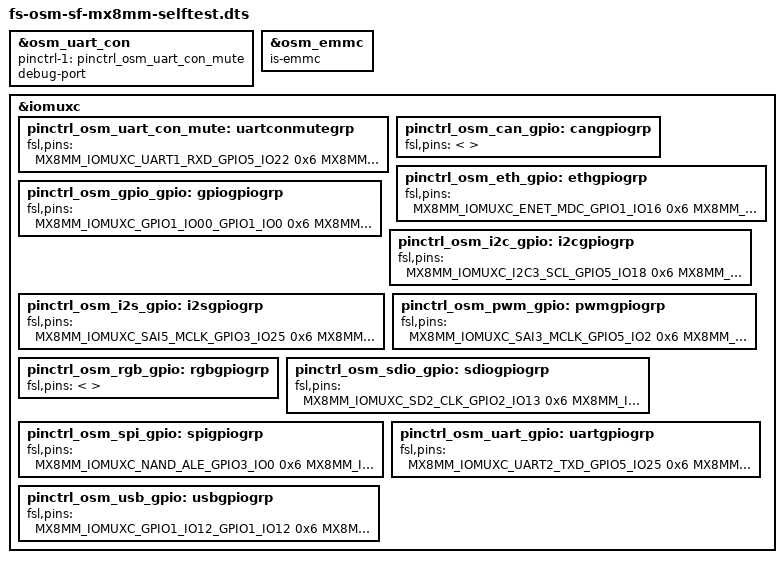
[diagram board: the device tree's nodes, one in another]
// SPDX-License-Identifier: GPL-2.0
/*
* Copyright 2024 F&S Elektronik Systeme GmbH
*
* This program is free software; you can redistribute it and/or modify
* it under the terms of the GNU General Public License version 2 as
* published by the Free Software Foundation.
*
* This program is distributed in the hope that it will be useful,
* but WITHOUT ANY WARRANTY; without even the implied warranty of
* MERCHANTABILITY or FITNESS FOR A PARTICULAR PURPOSE.  See the
* GNU General Public License for more details.
*/

/dts-v1/;
#include "osm8mm.dtsi"

&osm_uart_con { /* console */
	pinctrl-names = "default", "mute";
	pinctrl-1 = <&pinctrl_osm_uart_con_mute>;
	debug-port;
};

&osm_emmc {
	is-emmc;
};

#define gCAN_A_TX			<0>
#define gCAN_A_RX			<0>

#define gCAN_B_TX			<0>
#define gCAN_B_RX			<0>

#define gETH_MDC			<&gpio1 16 0>
#define gETH_MDIO			<&gpio1 17 0>
#define gETH_A_MII_TX_CLK	<&gpio1 23 0>
#define gETH_A_MII_TX_EN	<&gpio1 22 0>
#define gETH_A_MII_TXD0		<&gpio1 21 0>
#define gETH_A_MII_TXD1		<&gpio1 20 0>
#define gETH_A_MII_TXD2		<&gpio1 19 0>
#define gETH_A_MII_TXD3		<&gpio1 18 0>
#define gETH_A_MII_RX_CLK	<&gpio1 25 0>
#define gETH_A_MII_RX_DV	<&gpio1 24 0>
#define gETH_A_MII_RXD0		<&gpio1 26 0>
#define gETH_A_MII_RXD1		<&gpio1 27 0>
#define gETH_A_MII_RXD2		<&gpio1 28 0>
#define gETH_A_MII_RXD3		<&gpio1 29 0>

#define gETH_B_MDC			<0>
#define gETH_B_MDIO			<0>
#define gETH_B_MII_TX_CLK	<0>
#define gETH_B_MII_TX_EN	<0>
#define gETH_B_MII_TXD0		<0>
#define gETH_B_MII_TXD1		<0>
#define gETH_B_MII_TXD2		<0>
#define gETH_B_MII_TXD3		<0>
#define gETH_B_MII_RX_CLK	<0>
#define gETH_B_MII_RX_DV	<0>
#define gETH_B_MII_RXD0		<0>
#define gETH_B_MII_RXD1		<0>
#define gETH_B_MII_RXD2		<0>
#define gETH_B_MII_RXD3		<0>

#define gGPIO_A_0			<&gpio1 0 0>
#define gGPIO_A_1			<&gpio1 1 0>
#define gGPIO_A_2			<&gpio1 4 0>
#define gGPIO_A_3			<&gpio1 5 0>
#define gGPIO_A_4			<&gpio1 6 0>
#define gGPIO_A_5			<&gpio1 7 0>

#define gGPIO_B_0			<&gpio1 8 0>
#define gGPIO_B_1			<&gpio1 9 0>
#define gGPIO_B_2			<&gpio1 10 0>
#define gGPIO_B_3			<&gpio1 11 0>
#define gGPIO_B_4			<&gpio5 7 0>
#define gGPIO_B_5			<&gpio4 9 0>
#define gGPIO_B_6			<&gpio4 8 0>
#define gGPIO_B_7			<&gpio4 7 0>

#define gGPIO_C_0			<&gpio4 6 0>
#define gGPIO_C_1			<&gpio4 5 0>
#define gGPIO_C_2			<&gpio4 4 0>
#define gGPIO_C_3			<&gpio4 3 0>
/* GPIO_C_4 */
#define gDISP_VDD_EN		<&gpio5 1 0>
/* GPIO_C_5 */
#define gDISP_BL_EN			<&gpio5 0 0>
/* GPIO_C_6 */
#define gCAM_A_PWR			<&gpio4 25 0>
/* GPIO_C_7 */
#define gCAM_A_RST			<&gpio4 26 0>

#define gI2C_B_SCL			<&gpio5 18 0>
#define gI2C_B_SDA			<&gpio5 19 0>

#define gI2C_CAM_CK			<&gpio5 20 0>
#define gI2C_CAM_DAT		<&gpio5 21 0>

#define gI2S_MCLK			<&gpio3 25 0>
#define gI2S_LRCLK			<&gpio3 22 0>
#define gI2S_BITCLK			<&gpio3 23 0>
#define gI2S_A_DATA_OUT		<&gpio3 24 0>
#define gI2S_A_DATA_IN		<&gpio3 21 0>
#define gI2S_B_DATA_OUT		<0>
#define gI2S_B_DATA_IN		<0>

#define gDISP_BL_PWM		<&gpio5 2 0>
#define gPWM_1				<&gpio5 5 0>
#define gPWM_2				<&gpio5 4 0>
#define gPWM_3				<&gpio5 3 0>
#define gPWM_4				<0>
#define gPWM_5				<0>

#define gRGB_R0				<0>
#define gRGB_R1				<0>
#define gRGB_R2				<0>
#define gRGB_R3				<0>
#define gRGB_R4				<0>
#define gRGB_R5				<0>
#define gRGB_B0				<0>
#define gRGB_B1				<0>
#define gRGB_B2				<0>
#define gRGB_B3				<0>
#define gRGB_B4				<0>
#define gRGB_B5				<0>
#define gRGB_G0				<0>
#define gRGB_G1				<0>
#define gRGB_G2				<0>
#define gRGB_G3				<0>
#define gRGB_G4				<0>
#define gRGB_G5				<0>
#define gRGB_CLK			<0>
#define gRGB_DISP			<0>
#define gRGB_DE				<0>
#define gRGB_HSYNC			<0>
#define gRGB_VSYNC			<0>
#define gRGB_RESET			<0>

/* ATTENTION: Do not test SDIO_B_WP -> SDIO_A_CMD,
 * because they can have different voltage levels (1,8V/3,3V) */

#define gSDIO_A_CLK			<&gpio2 13 0>
/* Leave SDIO_A_CMD not defined! */
#define gSDIO_A_CMD			<0>
#define gSDIO_A_D0			<&gpio2 15 0>
#define gSDIO_A_D1			<&gpio2 16 0>
#define gSDIO_A_D2			<&gpio2 17 0>
#define gSDIO_A_D3			<&gpio2 18 0>
#define gSDIO_A_CD			<&gpio2 12 0>
#define gSDIO_A_WP			<&gpio2 20 0>
#define gSDIO_A_PWR_EN		<&gpio2 19 0>

#define gSDIO_B_CLK			<&gpio3 17 0>
#define gSDIO_B_CMD			<&gpio3 18 0>
#define gSDIO_B_D0			<&gpio3 10 0>
#define gSDIO_B_D1			<&gpio3 11 0>
#define gSDIO_B_D2			<&gpio3 12 0>
#define gSDIO_B_D3			<&gpio3 13 0>
#define gSDIO_B_D4			<&gpio3 15 0>
#define gSDIO_B_D5			<&gpio3 3 0>
#define gSDIO_B_D6			<&gpio3 4 0>
#define gSDIO_B_D7			<&gpio3 5 0>
#define gSDIO_B_CD			<&gpio4 22 0>
/* Leave SDIO_B_WP not defined! */
#define gSDIO_B_WP			<0>
#define gSDIO_B_PWR_EN		<&gpio3 16 0>

#define gSPI_A_SCK			<&gpio3 0 0>
#define gSPI_A_IO0			<&gpio3 6 0>
#define gSPI_A_IO1			<&gpio3 7 0>
#define gSPI_A_IO2			<&gpio3 8 0>
#define gSPI_A_IO3			<&gpio3 9 0>
#define gSPI_A_CS0			<&gpio3 1 0>
/* GPIO_A_6 */
#define gSPI_A_CS1			<&gpio3 2 0>

#define gSPI_B_SCK			<&gpio5 10 0>
#define gSPI_B_SDO			<&gpio5 11 0>
#define gSPI_B_SDI			<&gpio5 12 0>
#define gSPI_B_CS0			<&gpio5 13 0>
/* GPIO_A_7 */
#define gSPI_B_CS1			<&gpio5 6 0>

#define gUART_A_TX			<&gpio5 25 0>
#define gUART_A_RX			<&gpio5 24 0>
#define gUART_A_RTS			<&gpio4 29 0>
#define gUART_A_CTS			<&gpio4 30 0>

#define gUART_B_TX			<&gpio5 27 0>
#define gUART_B_RX			<&gpio5 26 0>
#define gUART_B_RTS			<&gpio5 8 0>
#define gUART_B_CTS			<&gpio5 9 0>

#define gUART_C_TX			<&gpio5 29 0>
#define gUART_C_RX			<&gpio5 28 0>

#define gUART_D_TX			<0>
#define gUART_D_RX			<0>

#define gUSB_A_EN			<&gpio1 12 0>
#define gUSB_A_OC			<&gpio1 13 0>


&iomuxc{
    /* debug output */
	pinctrl_osm_uart_con_mute: uartconmutegrp {
		fsl,pins = <
			MX8MM_IOMUXC_UART1_RXD_GPIO5_IO22	0x6
			MX8MM_IOMUXC_UART1_TXD_GPIO5_IO23	0x6
		>;
	};

	pinctrl_osm_can_gpio: cangpiogrp{
		fsl,pins = <
			/* CAN_A */
			/* NC */
			/* CAN_B */
			/* NC */
		>;
	};

	pinctrl_osm_eth_gpio: ethgpiogrp {
		fsl,pins = <
			/* ETH_A */
			MX8MM_IOMUXC_ENET_MDC_GPIO1_IO16		0x6
			MX8MM_IOMUXC_ENET_MDIO_GPIO1_IO17		0x6
			MX8MM_IOMUXC_ENET_TXC_GPIO1_IO23		0x6
			MX8MM_IOMUXC_ENET_TX_CTL_GPIO1_IO22		0x6
			MX8MM_IOMUXC_ENET_TD0_GPIO1_IO21		0x6
			MX8MM_IOMUXC_ENET_TD1_GPIO1_IO20		0x6
			MX8MM_IOMUXC_ENET_TD2_GPIO1_IO19		0x6
			MX8MM_IOMUXC_ENET_TD3_GPIO1_IO18		0x6
			MX8MM_IOMUXC_ENET_RXC_GPIO1_IO25		0x6
			MX8MM_IOMUXC_ENET_RX_CTL_GPIO1_IO24		0x6
			MX8MM_IOMUXC_ENET_RD0_GPIO1_IO26		0x6
			MX8MM_IOMUXC_ENET_RD1_GPIO1_IO27		0x6
			MX8MM_IOMUXC_ENET_RD2_GPIO1_IO28		0x6
			MX8MM_IOMUXC_ENET_RD3_GPIO1_IO29		0x6
			/* ETH_B */
			/* NC */
		>;
	};

	pinctrl_osm_gpio_gpio: gpiogpiogrp {
		fsl,pins = <
			/* GPIO_A */
			/* 0 */ MX8MM_IOMUXC_GPIO1_IO00_GPIO1_IO0	0x6
			/* 1 */ MX8MM_IOMUXC_GPIO1_IO01_GPIO1_IO1	0x6
			/* 2 */ MX8MM_IOMUXC_GPIO1_IO04_GPIO1_IO4	0x6
			/* 3 */ MX8MM_IOMUXC_GPIO1_IO05_GPIO1_IO5	0x6
			/* 4 */ MX8MM_IOMUXC_GPIO1_IO06_GPIO1_IO6	0x6
			/* 5 */ MX8MM_IOMUXC_GPIO1_IO07_GPIO1_IO7	0x6
			/* 6 */ /* optional to SPI_A_CS1 */
			/* 7 */ /* optional to SPI_B_CS1 */
			/* GPIO_B */
			/* 0 */ MX8MM_IOMUXC_GPIO1_IO08_GPIO1_IO8	0x6
			/* 1 */ MX8MM_IOMUXC_GPIO1_IO09_GPIO1_IO9	0x6
			/* 2 */ MX8MM_IOMUXC_GPIO1_IO10_GPIO1_IO10	0x6
			/* 3 */ MX8MM_IOMUXC_GPIO1_IO11_GPIO1_IO11	0x6
			/* 4 */ MX8MM_IOMUXC_ECSPI1_MOSI_GPIO5_IO7	0x6
			/* 5 */ MX8MM_IOMUXC_SAI1_RXD7_GPIO4_IO9	0x6
			/* 6 */ MX8MM_IOMUXC_SAI1_RXD6_GPIO4_IO8	0x6
			/* 7 */ MX8MM_IOMUXC_SAI1_RXD5_GPIO4_IO7	0x6
			/* GPIO_C */
			/* 0 */ MX8MM_IOMUXC_SAI1_RXD4_GPIO4_IO6	0x6
			/* 1 */ MX8MM_IOMUXC_SAI1_RXD3_GPIO4_IO5	0x6
			/* 2 */ MX8MM_IOMUXC_SAI1_RXD2_GPIO4_IO4	0x6
			/* 3 */ MX8MM_IOMUXC_SAI1_RXD1_GPIO4_IO3	0x6
			/* 4 DISP_VDD_EN */	MX8MM_IOMUXC_SAI3_TXD_GPIO5_IO1		0x6
			/* 5 DISP_BL_EN */	MX8MM_IOMUXC_SAI3_TXC_GPIO5_IO0		0x6
			/* 6 CAM_A_PWR */	MX8MM_IOMUXC_SAI2_TXC_GPIO4_IO25	0x6
			/* 7 CAM_A_RST */	MX8MM_IOMUXC_SAI2_TXD0_GPIO4_IO26	0x6
		>;
	};

	pinctrl_osm_i2c_gpio: i2cgpiogrp {
		fsl,pins = <
			/* I2C_B */
			MX8MM_IOMUXC_I2C3_SCL_GPIO5_IO18	0x6
			MX8MM_IOMUXC_I2C3_SDA_GPIO5_IO19	0x6
			/* I2C_CAM */
			MX8MM_IOMUXC_I2C4_SCL_GPIO5_IO20	0x6
			MX8MM_IOMUXC_I2C4_SDA_GPIO5_IO21	0x6
		>;
	};

	pinctrl_osm_i2s_gpio: i2sgpiogrp {
		fsl,pins = <
			/* I2S */
			MX8MM_IOMUXC_SAI5_MCLK_GPIO3_IO25	0x6
			MX8MM_IOMUXC_SAI5_RXD1_GPIO3_IO22	0x6
			MX8MM_IOMUXC_SAI5_RXD2_GPIO3_IO23	0x6
			/* I2S_A */
			MX8MM_IOMUXC_SAI5_RXD3_GPIO3_IO24	0x6
			MX8MM_IOMUXC_SAI5_RXD0_GPIO3_IO21	0x6
			/* I2S_B */
			/* NC */
		>;
	};

	pinctrl_osm_pwm_gpio: pwmgpiogrp {
		fsl,pins = <
			/* PWM */
			/* 0 DISP_BL_PWM */	MX8MM_IOMUXC_SAI3_MCLK_GPIO5_IO2	0x6
			/* 1 */ MX8MM_IOMUXC_SPDIF_EXT_CLK_GPIO5_IO5	0x6
			/* 2 */ MX8MM_IOMUXC_SPDIF_RX_GPIO5_IO4			0x6
			/* 3 */ MX8MM_IOMUXC_SPDIF_TX_GPIO5_IO3			0x6
			/* 4-5 NC */
		>;
	};

	pinctrl_osm_rgb_gpio: rgbgpiogrp {
		fsl,pins = <
			/* RGB */
			/* NC */
		>;
	};

	pinctrl_osm_sdio_gpio: sdiogpiogrp {
		fsl,pins = <
			/* SDIO_A */
			MX8MM_IOMUXC_SD2_CLK_GPIO2_IO13			0x6
			MX8MM_IOMUXC_SD2_CMD_GPIO2_IO14			0x6
			MX8MM_IOMUXC_SD2_DATA0_GPIO2_IO15		0x6
			MX8MM_IOMUXC_SD2_DATA1_GPIO2_IO16		0x6
			MX8MM_IOMUXC_SD2_DATA2_GPIO2_IO17		0x6
			MX8MM_IOMUXC_SD2_DATA3_GPIO2_IO18		0x6
			MX8MM_IOMUXC_SD2_CD_B_GPIO2_IO12		0x6
			MX8MM_IOMUXC_SD2_WP_GPIO2_IO20			0x6
			MX8MM_IOMUXC_SD2_RESET_B_GPIO2_IO19		0x6
			/* SDIO_B */
			MX8MM_IOMUXC_NAND_WE_B_GPIO3_IO17		0x6
			MX8MM_IOMUXC_NAND_WP_B_GPIO3_IO18		0x6
			MX8MM_IOMUXC_NAND_DATA04_GPIO3_IO10		0x6
			MX8MM_IOMUXC_NAND_DATA05_GPIO3_IO11		0x6
			MX8MM_IOMUXC_NAND_DATA06_GPIO3_IO12		0x6
			MX8MM_IOMUXC_NAND_DATA07_GPIO3_IO13		0x6
			MX8MM_IOMUXC_NAND_RE_B_GPIO3_IO15		0x6
			MX8MM_IOMUXC_NAND_CE2_B_GPIO3_IO3		0x6
			MX8MM_IOMUXC_NAND_CE3_B_GPIO3_IO4		0x6
			MX8MM_IOMUXC_NAND_CLE_GPIO3_IO5			0x6
			MX8MM_IOMUXC_SAI2_RXC_GPIO4_IO22		0x6
			MX8MM_IOMUXC_SAI2_RXD0_GPIO4_IO23		0x6
			MX8MM_IOMUXC_NAND_READY_B_GPIO3_IO16	0x6
		>;
	};

	pinctrl_osm_spi_gpio: spigpiogrp {
		fsl,pins = <
			/* SPI_A */
			MX8MM_IOMUXC_NAND_ALE_GPIO3_IO0			0x6
			MX8MM_IOMUXC_NAND_DATA00_GPIO3_IO6		0x6
			MX8MM_IOMUXC_NAND_DATA01_GPIO3_IO7		0x6
			MX8MM_IOMUXC_NAND_DATA02_GPIO3_IO8		0x6
			MX8MM_IOMUXC_NAND_DATA03_GPIO3_IO9		0x6
			MX8MM_IOMUXC_NAND_CE0_B_GPIO3_IO1		0x6
			MX8MM_IOMUXC_NAND_CE1_B_GPIO3_IO2		0x6
			/* SPI_B */
			MX8MM_IOMUXC_ECSPI2_SCLK_GPIO5_IO10		0x6
			MX8MM_IOMUXC_ECSPI2_MOSI_GPIO5_IO11		0x6
			MX8MM_IOMUXC_ECSPI2_MISO_GPIO5_IO12		0x6
			MX8MM_IOMUXC_ECSPI2_SS0_GPIO5_IO13		0x6
			MX8MM_IOMUXC_ECSPI1_SCLK_GPIO5_IO6		0x6
		>;
	};

	pinctrl_osm_uart_gpio: uartgpiogrp{
		fsl,pins = <
			/* UART_A */
			MX8MM_IOMUXC_UART2_TXD_GPIO5_IO25		0x6
			MX8MM_IOMUXC_UART2_RXD_GPIO5_IO24		0x6
			MX8MM_IOMUXC_SAI3_RXC_GPIO4_IO29		0x6
			MX8MM_IOMUXC_SAI3_RXD_GPIO4_IO30		0x6
			/* UART_B */
			MX8MM_IOMUXC_UART3_TXD_GPIO5_IO27		0x6
			MX8MM_IOMUXC_UART3_RXD_GPIO5_IO26		0x6
			MX8MM_IOMUXC_ECSPI1_MISO_GPIO5_IO8		0x6
			MX8MM_IOMUXC_ECSPI1_SS0_GPIO5_IO9		0x6
			/* UART_C */
			MX8MM_IOMUXC_UART4_TXD_GPIO5_IO29		0x6
			MX8MM_IOMUXC_UART4_RXD_GPIO5_IO28		0x6
			/* UART_D */
			/* NC */
		>;
	};

	pinctrl_osm_usb_gpio: usbgpiogrp{
		fsl,pins = <
			/* USB_A */
			MX8MM_IOMUXC_GPIO1_IO12_GPIO1_IO12		0x6
			MX8MM_IOMUXC_GPIO1_IO13_GPIO1_IO13		0x6
		>;
	};
};
